# WE2_S_NS register map
Vendor: ARM Ltd.; Series: ARMv8.1-M Mainline; File version: 1.0
CPU: CM55 r1p1, little endian, MPU, FPU, double-precision FPU, DSP, VTOR, 3 interrupt priority bits
Registers are 32-bit, read-write, reset 0x0 unless marked. A register's access mark holds for its fields unless they carry their own. Offsets are from the block's base; [hi:lo] are bit positions; {n}, {i} and the like mark numbered series; 'fields as' and 'values as' point back to an identical list.

## SYS_PMU — Performance Monitoring Unit
Base 0xE0003000
{0x0+4i} PMU_EVCNTR{i} (i=0..7) — Performance Monitoring Unit Event Counter Register {i}
0x7C PMU_CCNTR — Performance Monitoring Unit Cycle Counter Register
{0x400+4i} PMU_EVTYPER{i} 16-bit (i=0..7) — Performance Monitoring Unit Event Type and Filter Register {i}
0x47C PMU_CCFILTR ro
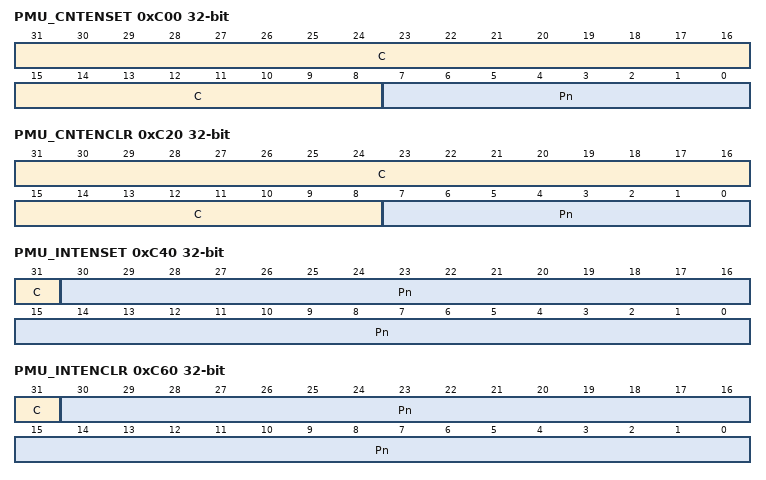
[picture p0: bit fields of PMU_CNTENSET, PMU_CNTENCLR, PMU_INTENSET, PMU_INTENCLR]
0xC00 PMU_CNTENSET — Performance Monitoring Unit Count Enable Set Register
  [31:8] C — PMU_CCNTR enable bit
  [7:0] Pn — Event counter PMU_EVCNTR0-7 enable bit
0xC20 PMU_CNTENCLR — Performance Monitoring Unit Count Enable Clear Register
  fields as PMU_CNTENSET
0xC40 PMU_INTENSET — Performance Monitoring Unit Interrupt Enable Set Register
  [31] C — PMU_CCNTR interrupt request enable bit
  [30:0] Pn — Event counter overflow interrupt request disable bit for PMU_EVCNTRn. Disable the overflow interrupt for PMU_EVCNTRn
0xC60 PMU_INTENCLR — Performance Monitoring Unit Interrupt Enable Clear Register
  [31] C — PMU_CCNTR overflow interrupt request disable bit
  [30:0] Pn — Event counter overflow interrupt request enable bit for PMU_EVCNTRn. Enable the overflow interrupt for PMU_EVCNTRn
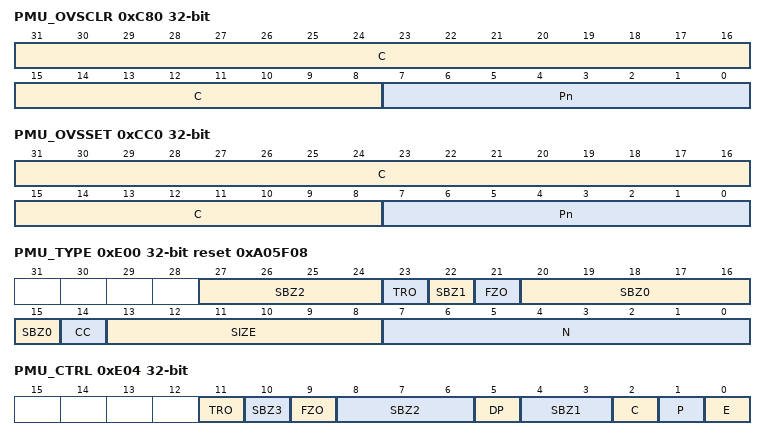
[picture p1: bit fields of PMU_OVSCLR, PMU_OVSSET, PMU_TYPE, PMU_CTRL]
0xC80 PMU_OVSCLR — Performance Monitoring Unit Overflow Flag Status Clear Register
  [31:8] C — PMU_CCNTR overflow bit. Clears the PMU_CCNTR overflow bit
  [7:0] Pn — Event counter overflow clear bit for PMU_EVCNTRn. Clears the PMU_EVCNTRn overflow bit
0xCA0 PMU_SWINC — Performance Monitoring Unit Software Increment Register
  [30:0] Pn wo — Event counter overflow clear bit for PMU_EVCNTRn. Clears the PMU_EVCNTRn overflow bit
0xCC0 PMU_OVSSET — Performance Monitoring Unit Overflow Flag Status Set Register
  [31:8] C — PMU_CCNTR overflow bit. Sets the overflow status for PMU_CCNTR
  [7:0] Pn — Event counter overflow set bit for PMU_EVCNTRn. Sets the overflow status for PMU_EVCNTRn
0xE00 PMU_TYPE ro reset 0xA05F08 — Performance Monitoring Unit Software Increment Register
  [27:24] SBZ2
  [23] TRO
  [22] SBZ1
  [21] FZO — Freeze-on-overflow is supported
  [20:15] SBZ0
  [14] CC — A dedicated cycle counter is present
  [13:8] SIZE
  [7:0] N — Number of counters
0xE04 PMU_CTRL — Performance Monitoring Unit Control Register
  [11] TRO
  [10] SBZ3
  [9] FZO — Freeze-on-overflow. Stops events being counted once PMU_OVSCLR or PMU_OVSSET is non-zero.description
  [8:6] SBZ2
  [5] DP — Disable cycle counter when event counting is prohibited
  [4:3] SBZ1
  [2] C — Cycle counter reset. Reset the PMU_CCNTR counter
  [1] P — Event counter reset
  [0] E — Enable. Enable the event counters
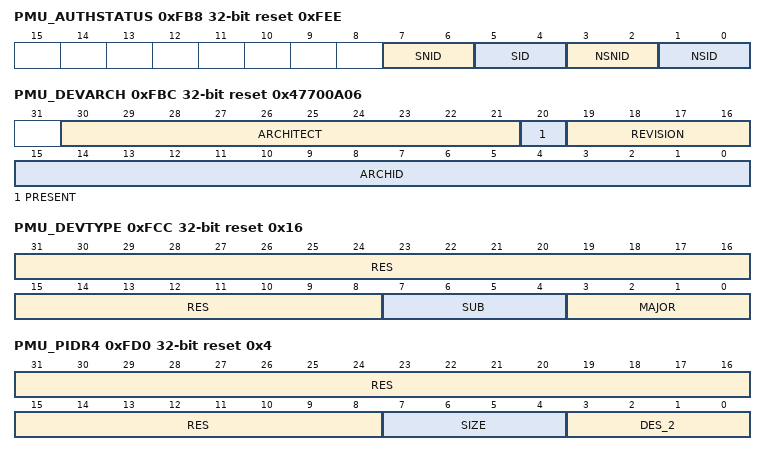
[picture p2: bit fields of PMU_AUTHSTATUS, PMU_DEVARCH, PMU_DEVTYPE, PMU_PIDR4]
0xFB8 PMU_AUTHSTATUS ro reset 0xFEE (reset mask 0xFF00FF00) — Performance Monitoring Unit Authentication Status Register
  [7:6] SNID — Secure Non-invasive Debug. Indicates whether Secure Non-invasive debug is implemented and allowed
    on read: 0=SecurityExtensionNotImplemented; 1=RES_01 (Reserved_); 2=SNID_NotAllowed (Security Extension implemented and Secure Non-invasive debug not allowed); 3=SNID_Allowed (Security Extension implemented and Secure Non-invasive debug allowed)
  [5:4] SID — Secure Invasive Debug. Indicates whether Secure invasive debug is implemented and allowed
    on read: 0=SecurityExtensionNotImplemented; 1=RES_01 (Reserved_); 2=SID_NotAllowed (Security Extension implemented and Secure invasive debug not allowed); 3=SID_Allowed (Security Extension implemented and Secure invasive debug allowed)
  [3:2] NSNID — Non-secure Non-invasive Debug. Indicates whether Non-secure Non-invasive debug is allowed
    on read: 0=RES_00 (Reserved_); 1=RES_01 (Reserved_); 2=NSNID_NotAllowed (Non-secure Non-invasive debug not allowed); 3=NSNID_Allowed (Non-secure Non-invasive debug allowed)
  [1:0] NSID — Non-secure Invasive Debug. Indicates whether Non-secure invasive debug is allowed
    on read: 0=RES_00 (Reserved_); 1=RES_01 (Reserved_); 2=NSID_NotAllowed (Non-secure invasive debug not allowed); 3=NSID_Allowed (Non-secure invasive debug allowed)
0xFBC PMU_DEVARCH ro reset 0x47700A06 — Performance Monitoring Unit Device Architecture Register
  [30:21] ARCHITECT — Defines the architecture of the component. For the PMU, it is Arm Limited. Bits[31:28] are the JEP 106 continuation code, 0x4, and bits [27:21] are the JEP 106 ID code, 0x3B.
  [20] PRESENT — Determines the presence of DEVARCH. When set to 1, indicates that the DEVARCH is present. This bit reads as 0x1
  [19:16] REVISION — Defines the architecture revision. For the PMU, the revision defined by Armv8.1-M is 0x2
  [15:0] ARCHID — Defines this part to be an Armv8-M debug component. For the PMU, bits [15:12] are 0x0, bits [11:0] are 0xA06
0xFCC PMU_DEVTYPE ro reset 0x16 — Performance Monitoring Unit Device Type Register
  [31:8] RES — RES0
  [7:4] SUB — Subtype. This field reads as 0x1
  [3:0] MAJOR — Major type. This field reads as 0x6
0xFD0 PMU_PIDR4 ro reset 0x4 — Performance Monitoring Unit Peripheral Identification Register 4
  [31:8] RES — RES0
  [7:4] SIZE — Size of the component. This field is RAZ.
  [3:0] DES_2 — Designer, JEP 106 continuation code, least significant nibble. For Arm Limited, this field is 0x4
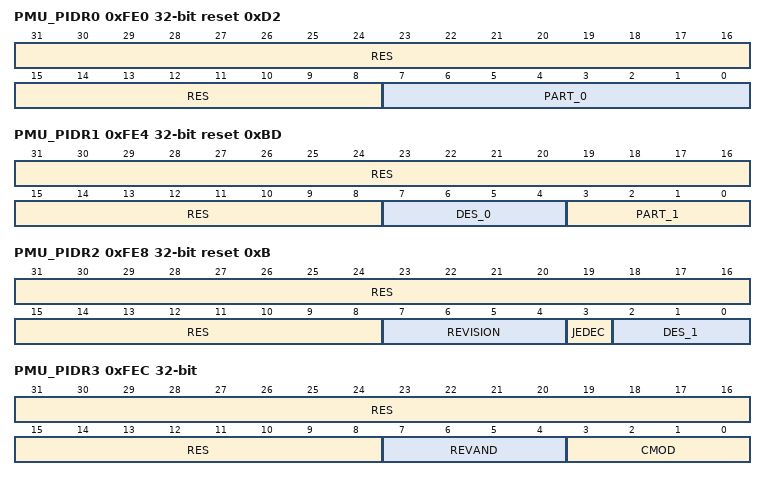
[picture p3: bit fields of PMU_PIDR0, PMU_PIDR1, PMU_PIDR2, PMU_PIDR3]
0xFE0 PMU_PIDR0 ro reset 0xD2 — Performance Monitoring Unit Peripheral Identification Register 0
  [31:8] RES — RES0
  [7:0] PART_0 — Part number, least significant byte. This field reads 0x22
0xFE4 PMU_PIDR1 ro reset 0xBD — Performance Monitoring Unit Peripheral Identification Register 1
  [31:8] RES — RES0
  [7:4] DES_0 — Designer, least significant nibble of JEP 106 ID code. For Arm Limited, this field 0xB
  [3:0] PART_1 — Part number, least significant byte. This field reads 0x22
0xFE8 PMU_PIDR2 ro reset 0xB — Performance Monitoring Unit Peripheral Identification Register 2
  [31:8] RES — RES0
  [7:4] REVISION — Part major revision
  [3] JEDEC — Indicates a JEP10 identity code. This is RAO
  [2:0] DES_1 — Designer, most significant bits of JEP 106 ID code. For Arm Limited, this field 0b011
0xFEC PMU_PIDR3 ro — Performance Monitoring Unit Peripheral Identification Register 3
  [31:8] RES — RES0
  [7:4] REVAND — Part minor revision
  [3:0] CMOD — Customer modified
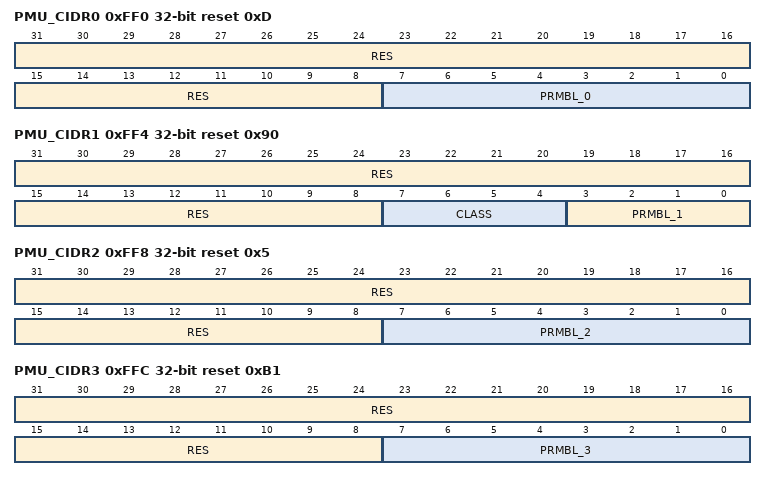
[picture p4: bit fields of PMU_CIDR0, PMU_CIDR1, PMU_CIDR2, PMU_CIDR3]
0xFF0 PMU_CIDR0 ro reset 0xD — Performance Monitoring Unit Component Identification Register 0
  [31:8] RES — RES0
  [7:0] PRMBL_0 — Preamble. This field reads 0x0D
0xFF4 PMU_CIDR1 ro reset 0x90 — Performance Monitoring Unit Component Identification Register 1
  [31:8] RES — RES0
  [7:4] CLASS — Component class. This field reads 0x0
  [3:0] PRMBL_1 — Preamble. This field reads 0x0
0xFF8 PMU_CIDR2 ro reset 0x5 — Performance Monitoring Unit Component Identification Register 2
  [31:8] RES — RES0
  [7:0] PRMBL_2 — Preamble. This field reads 0x05
0xFFC PMU_CIDR3 ro reset 0xB1 — Performance Monitoring Unit Component Identification Register 3
  [31:8] RES — RES0
  [7:0] PRMBL_3 — Preamble. This field reads 0xB1

## Notices in the file
Copyright (C) 2012 - 2020 Arm Limited. All rights reserved.
Purpose: System Viewer Description (SVD) Example (Schema Version 1.1)
This is a description of a none-existent and incomplete device
for demonstration purposes only.
Redistribution and use in source and binary forms, with or without
modification, are permitted provided that the following conditions are met:
- Redistributions of source code must retain the above copyright
notice, this list of conditions and the following disclaimer.
- Redistributions in binary form must reproduce the above copyright
notice, this list of conditions and the following disclaimer in the
documentation and/or other materials provided with the distribution.
- Neither the name of ARM nor the names of its contributors may be used
to endorse or promote products derived from this software without
specific prior written permission.
THIS SOFTWARE IS PROVIDED BY THE COPYRIGHT HOLDERS AND CONTRIBUTORS "AS IS"
AND ANY EXPRESS OR IMPLIED WARRANTIES, INCLUDING, BUT NOT LIMITED TO, THE
IMPLIED WARRANTIES OF MERCHANTABILITY AND FITNESS FOR A PARTICULAR PURPOSE
ARE DISCLAIMED. IN NO EVENT SHALL COPYRIGHT HOLDERS AND CONTRIBUTORS BE
LIABLE FOR ANY DIRECT, INDIRECT, INCIDENTAL, SPECIAL, EXEMPLARY, OR
CONSEQUENTIAL DAMAGES (INCLUDING, BUT NOT LIMITED TO, PROCUREMENT OF
SUBSTITUTE GOODS OR SERVICES; LOSS OF USE, DATA, OR PROFITS; OR BUSINESS
INTERRUPTION) HOWEVER CAUSED AND ON ANY THEORY OF LIABILITY, WHETHER IN
CONTRACT, STRICT LIABILITY, OR TORT (INCLUDING NEGLIGENCE OR OTHERWISE)
ARISING IN ANY WAY OUT OF THE USE OF THIS SOFTWARE, EVEN IF ADVISED OF THE
POSSIBILITY OF SUCH DAMAGE.
